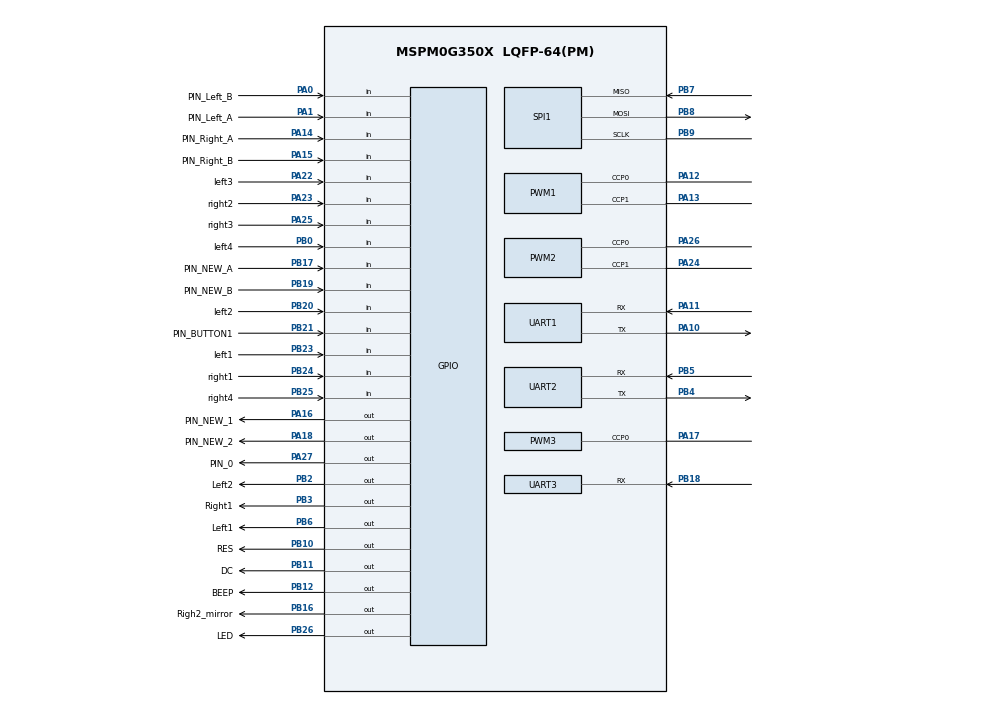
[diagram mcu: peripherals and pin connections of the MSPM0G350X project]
/**
 * @cliArgs --device "MSPM0G350X" --part "Default" --package "LQFP-64(PM)" --product "mspm0_sdk@2.10.00.04"
 * @versions {"tool":"1.26.2+4477"}
 */

/**
 * Import the modules used in this configuration.
 */
const GPIO    = scripting.addModule("/ti/driverlib/GPIO", {}, false);
const GPIO1   = GPIO.addInstance();
const GPIO2   = GPIO.addInstance();
const GPIO3   = GPIO.addInstance();
const GPIO4   = GPIO.addInstance();
const GPIO5   = GPIO.addInstance();
const GPIO6   = GPIO.addInstance();
const GPIO7   = GPIO.addInstance();
const GPIO8   = GPIO.addInstance();
const PWM     = scripting.addModule("/ti/driverlib/PWM", {}, false);
const PWM1    = PWM.addInstance();
const PWM2    = PWM.addInstance();
const PWM3    = PWM.addInstance();
const SPI     = scripting.addModule("/ti/driverlib/SPI", {}, false);
const SPI1    = SPI.addInstance();
const SYSCTL  = scripting.addModule("/ti/driverlib/SYSCTL");
const SYSTICK = scripting.addModule("/ti/driverlib/SYSTICK");
const TIMER   = scripting.addModule("/ti/driverlib/TIMER", {}, false);
const TIMER1  = TIMER.addInstance();
const UART    = scripting.addModule("/ti/driverlib/UART", {}, false);
const UART1   = UART.addInstance();
const UART2   = UART.addInstance();
const UART3   = UART.addInstance();

/**
 * Write custom configuration values to the imported modules.
 */
GPIO1.$name                         = "GPIO_MOTOR";
GPIO1.associatedPins.create(4);
GPIO1.associatedPins[0].$name       = "Left1";
GPIO1.associatedPins[0].pin.$assign = "PB6";
GPIO1.associatedPins[1].$name       = "Left2";
GPIO1.associatedPins[1].pin.$assign = "PB2";
GPIO1.associatedPins[2].$name       = "Right1";
GPIO1.associatedPins[2].pin.$assign = "PB3";
GPIO1.associatedPins[3].$name       = "Righ2_mirror";
GPIO1.associatedPins[3].pin.$assign = "PB16";

const Board = scripting.addModule("/ti/driverlib/Board", {}, false);

GPIO2.$name                          = "GPIO_LED";
GPIO2.associatedPins.create(2);
GPIO2.associatedPins[0].$name        = "LED";
GPIO2.associatedPins[0].initialValue = "SET";
GPIO2.associatedPins[0].pin.$assign  = "PB26";
GPIO2.associatedPins[1].$name        = "BEEP";
GPIO2.associatedPins[1].pin.$assign  = "PB12";

GPIO3.$name                         = "GPIO_Encoder";
GPIO3.associatedPins.create(6);
GPIO3.associatedPins[0].$name       = "PIN_Left_A";
GPIO3.associatedPins[0].direction   = "INPUT";
GPIO3.associatedPins[0].interruptEn = true;
GPIO3.associatedPins[0].polarity    = "RISE";
GPIO3.associatedPins[0].pin.$assign = "PA1";
GPIO3.associatedPins[1].$name       = "PIN_Left_B";
GPIO3.associatedPins[1].direction   = "INPUT";
GPIO3.associatedPins[1].pin.$assign = "PA0";
GPIO3.associatedPins[2].$name       = "PIN_Right_A";
GPIO3.associatedPins[2].direction   = "INPUT";
GPIO3.associatedPins[2].interruptEn = true;
GPIO3.associatedPins[2].polarity    = "RISE";
GPIO3.associatedPins[2].pin.$assign = "PA14";
GPIO3.associatedPins[3].$name       = "PIN_Right_B";
GPIO3.associatedPins[3].direction   = "INPUT";
GPIO3.associatedPins[3].pin.$assign = "PA15";
GPIO3.associatedPins[4].$name       = "PIN_NEW_A";
GPIO3.associatedPins[4].direction   = "INPUT";
GPIO3.associatedPins[4].polarity    = "RISE";
GPIO3.associatedPins[4].interruptEn = true;
GPIO3.associatedPins[4].pin.$assign = "PB17";
GPIO3.associatedPins[5].$name       = "PIN_NEW_B";
GPIO3.associatedPins[5].direction   = "INPUT";
GPIO3.associatedPins[5].pin.$assign = "PB19";

GPIO4.$name                              = "GPIO_BUTTON";
GPIO4.associatedPins.create(3);
GPIO4.associatedPins[0].$name            = "PIN_BUTTON1";
GPIO4.associatedPins[0].direction        = "INPUT";
GPIO4.associatedPins[0].internalResistor = "PULL_UP";
GPIO4.associatedPins[0].pin.$assign      = "PB21";
GPIO4.associatedPins[1].direction        = "INPUT";
GPIO4.associatedPins[1].internalResistor = "PULL_UP";
GPIO4.associatedPins[1].$name            = "PIN_BUTTON2";
GPIO4.associatedPins[2].$name            = "PIN_BUTTON3";
GPIO4.associatedPins[2].direction        = "INPUT";
GPIO4.associatedPins[2].internalResistor = "PULL_UP";

GPIO5.$name                         = "GPIO_Traking";
GPIO5.associatedPins.create(8);
GPIO5.associatedPins[0].direction   = "INPUT";
GPIO5.associatedPins[0].$name       = "left4";
GPIO5.associatedPins[0].pin.$assign = "PB0";
GPIO5.associatedPins[1].direction   = "INPUT";
GPIO5.associatedPins[1].$name       = "left3";
GPIO5.associatedPins[1].pin.$assign = "PA22";
GPIO5.associatedPins[2].direction   = "INPUT";
GPIO5.associatedPins[2].$name       = "left2";
GPIO5.associatedPins[2].pin.$assign = "PB20";
GPIO5.associatedPins[3].direction   = "INPUT";
GPIO5.associatedPins[3].$name       = "left1";
GPIO5.associatedPins[3].pin.$assign = "PB23";
GPIO5.associatedPins[4].direction   = "INPUT";
GPIO5.associatedPins[4].$name       = "right1";
GPIO5.associatedPins[4].pin.$assign = "PB24";
GPIO5.associatedPins[5].direction   = "INPUT";
GPIO5.associatedPins[5].$name       = "right2";
GPIO5.associatedPins[5].pin.$assign = "PA23";
GPIO5.associatedPins[6].direction   = "INPUT";
GPIO5.associatedPins[6].$name       = "right3";
GPIO5.associatedPins[6].pin.$assign = "PA25";
GPIO5.associatedPins[7].direction   = "INPUT";
GPIO5.associatedPins[7].$name       = "right4";
GPIO5.associatedPins[7].pin.$assign = "PB25";

GPIO6.$name                         = "OLED";
GPIO6.port                          = "PORTB";
GPIO6.associatedPins.create(3);
GPIO6.associatedPins[0].$name       = "RES";
GPIO6.associatedPins[0].ioStructure = "SD";
GPIO6.associatedPins[0].assignedPin = "10";
GPIO6.associatedPins[0].pin.$assign = "PB10";
GPIO6.associatedPins[1].$name       = "CS";
GPIO6.associatedPins[1].ioStructure = "SD";
GPIO6.associatedPins[1].assignedPin = "14";
GPIO6.associatedPins[2].$name       = "DC";
GPIO6.associatedPins[2].ioStructure = "SD";
GPIO6.associatedPins[2].assignedPin = "11";
GPIO6.associatedPins[2].pin.$assign = "PB11";

GPIO7.$name                         = "GPIO_MOTOR_NEW";
GPIO7.associatedPins.create(2);
GPIO7.associatedPins[0].$name       = "PIN_NEW_1";
GPIO7.associatedPins[0].pin.$assign = "PA16";
GPIO7.associatedPins[1].$name       = "PIN_NEW_2";
GPIO7.associatedPins[1].pin.$assign = "PA18";

GPIO8.$name                         = "GPIO_Voice";
GPIO8.associatedPins[0].$name       = "PIN_0";
GPIO8.associatedPins[0].pin.$assign = "PA27";

PWM1.$name                              = "PWM_MOTOR";
PWM1.timerCount                         = 3200;
PWM1.timerStartTimer                    = true;
PWM1.peripheral.ccp0Pin.$assign         = "PA12";
PWM1.peripheral.ccp1Pin.$assign         = "PA13";
PWM1.PWM_CHANNEL_0.$name                = "ti_driverlib_pwm_PWMTimerCC0";
PWM1.PWM_CHANNEL_1.$name                = "ti_driverlib_pwm_PWMTimerCC1";
PWM1.ccp0PinConfig.$name                = "ti_driverlib_gpio_GPIOPinGeneric0";
PWM1.ccp0PinConfig.direction            = scripting.forceWrite("OUTPUT");
PWM1.ccp0PinConfig.hideOutputInversion  = scripting.forceWrite(false);
PWM1.ccp0PinConfig.onlyInternalResistor = scripting.forceWrite(false);
PWM1.ccp0PinConfig.passedPeripheralType = scripting.forceWrite("Digital");
PWM1.ccp1PinConfig.$name                = "ti_driverlib_gpio_GPIOPinGeneric1";
PWM1.ccp1PinConfig.direction            = scripting.forceWrite("OUTPUT");
PWM1.ccp1PinConfig.hideOutputInversion  = scripting.forceWrite(false);
PWM1.ccp1PinConfig.onlyInternalResistor = scripting.forceWrite(false);
PWM1.ccp1PinConfig.passedPeripheralType = scripting.forceWrite("Digital");

PWM2.$name                              = "PWM_SEROR";
PWM2.clockPrescale                      = 32;
PWM2.timerCount                         = 20000;
PWM2.timerStartTimer                    = true;
PWM2.peripheral.$assign                 = "TIMG7";
PWM2.peripheral.ccp0Pin.$assign         = "PA26";
PWM2.peripheral.ccp1Pin.$assign         = "PA24";
PWM2.PWM_CHANNEL_0.$name                = "ti_driverlib_pwm_PWMTimerCC2";
PWM2.PWM_CHANNEL_1.$name                = "ti_driverlib_pwm_PWMTimerCC3";
PWM2.ccp0PinConfig.direction            = scripting.forceWrite("OUTPUT");
PWM2.ccp0PinConfig.hideOutputInversion  = scripting.forceWrite(false);
PWM2.ccp0PinConfig.onlyInternalResistor = scripting.forceWrite(false);
PWM2.ccp0PinConfig.passedPeripheralType = scripting.forceWrite("Digital");
PWM2.ccp0PinConfig.$name                = "ti_driverlib_gpio_GPIOPinGeneric9";
PWM2.ccp1PinConfig.direction            = scripting.forceWrite("OUTPUT");
PWM2.ccp1PinConfig.hideOutputInversion  = scripting.forceWrite(false);
PWM2.ccp1PinConfig.onlyInternalResistor = scripting.forceWrite(false);
PWM2.ccp1PinConfig.passedPeripheralType = scripting.forceWrite("Digital");
PWM2.ccp1PinConfig.$name                = "ti_driverlib_gpio_GPIOPinGeneric10";

PWM3.timerCount                         = 3200;
PWM3.timerStartTimer                    = true;
PWM3.ccIndex                            = [0];
PWM3.$name                              = "PWM_SEROR_NEW";
PWM3.PWM_CHANNEL_0.$name                = "ti_driverlib_pwm_PWMTimerCC4";
PWM3.ccp0PinConfig.direction            = scripting.forceWrite("OUTPUT");
PWM3.ccp0PinConfig.hideOutputInversion  = scripting.forceWrite(false);
PWM3.ccp0PinConfig.onlyInternalResistor = scripting.forceWrite(false);
PWM3.ccp0PinConfig.passedPeripheralType = scripting.forceWrite("Digital");
PWM3.ccp0PinConfig.$name                = "ti_driverlib_gpio_GPIOPinGeneric11";
PWM3.peripheral.$assign                 = "TIMA1";
PWM3.peripheral.ccp0Pin.$assign         = "PA17";

SPI1.$name                              = "SPI_OLED";
SPI1.frameFormat                        = "MOTO3";
SPI1.sclkPinConfig.$name                = "ti_driverlib_gpio_GPIOPinGeneric6";
SPI1.sclkPinConfig.direction            = scripting.forceWrite("OUTPUT");
SPI1.sclkPinConfig.onlyInternalResistor = scripting.forceWrite(false);
SPI1.sclkPinConfig.passedPeripheralType = scripting.forceWrite("Digital");
SPI1.mosiPinConfig.$name                = "ti_driverlib_gpio_GPIOPinGeneric7";
SPI1.mosiPinConfig.direction            = scripting.forceWrite("OUTPUT");
SPI1.mosiPinConfig.hideOutputInversion  = scripting.forceWrite(false);
SPI1.mosiPinConfig.onlyInternalResistor = scripting.forceWrite(false);
SPI1.mosiPinConfig.passedPeripheralType = scripting.forceWrite("Digital");
SPI1.misoPinConfig.$name                = "ti_driverlib_gpio_GPIOPinGeneric8";
SPI1.misoPinConfig.onlyInternalResistor = scripting.forceWrite(false);
SPI1.misoPinConfig.passedPeripheralType = scripting.forceWrite("Digital");
SPI1.peripheral.$assign                 = "SPI1";
SPI1.peripheral.sclkPin.$assign         = "PB9";
SPI1.peripheral.mosiPin.$assign         = "PB8";
SPI1.peripheral.misoPin.$assign         = "PB7";

SYSCTL.forceDefaultClkConfig = true;

SYSTICK.periodEnable      = true;
SYSTICK.period            = 32000;
SYSTICK.interruptEnable   = true;
SYSTICK.systickEnable     = true;
SYSTICK.interruptPriority = "0";

TIMER1.$name             = "TIMER_0";
TIMER1.timerClkDiv       = 4;
TIMER1.timerStartTimer   = true;
TIMER1.timerMode         = "PERIODIC";
TIMER1.interrupts        = ["ZERO"];
TIMER1.interruptPriority = "2";
TIMER1.timerPeriod       = "10ms";
TIMER1.timerClkPrescale  = 25;

UART1.$name                    = "UART_0";
UART1.enabledInterrupts        = ["RX"];
UART1.peripheral.rxPin.$assign = "PA11";
UART1.peripheral.txPin.$assign = "PA10";
UART1.txPinConfig.$name        = "ti_driverlib_gpio_GPIOPinGeneric2";
UART1.rxPinConfig.$name        = "ti_driverlib_gpio_GPIOPinGeneric3";

UART2.$name                            = "UART_OpenMv";
UART2.targetBaudRate                   = 115200;
UART2.enabledInterrupts                = ["RX"];
UART2.peripheral.rxPin.$assign         = "PB5";
UART2.peripheral.txPin.$assign         = "PB4";
UART2.txPinConfig.direction            = scripting.forceWrite("OUTPUT");
UART2.txPinConfig.hideOutputInversion  = scripting.forceWrite(false);
UART2.txPinConfig.onlyInternalResistor = scripting.forceWrite(false);
UART2.txPinConfig.passedPeripheralType = scripting.forceWrite("Digital");
UART2.txPinConfig.$name                = "ti_driverlib_gpio_GPIOPinGeneric4";
UART2.rxPinConfig.hideOutputInversion  = scripting.forceWrite(false);
UART2.rxPinConfig.onlyInternalResistor = scripting.forceWrite(false);
UART2.rxPinConfig.passedPeripheralType = scripting.forceWrite("Digital");
UART2.rxPinConfig.$name                = "ti_driverlib_gpio_GPIOPinGeneric5";

UART3.$name                            = "UART_WIT";
UART3.targetBaudRate                   = 115200;
UART3.direction                        = "RX";
UART3.enableFIFO                       = true;
UART3.rxTimeoutValue                   = 1;
UART3.enabledInterrupts                = ["RX_TIMEOUT_ERROR"];
UART3.enabledDMARXTriggers             = "DL_UART_DMA_INTERRUPT_RX";
UART3.rxPinConfig.hideOutputInversion  = scripting.forceWrite(false);
UART3.rxPinConfig.onlyInternalResistor = scripting.forceWrite(false);
UART3.rxPinConfig.passedPeripheralType = scripting.forceWrite("Digital");
UART3.rxPinConfig.$name                = "ti_driverlib_gpio_GPIOPinGeneric12";
UART3.peripheral.$assign               = "UART2";
UART3.peripheral.rxPin.$assign         = "PB18";
UART3.DMA_CHANNEL_RX.$name             = "DMA_WIT";
UART3.DMA_CHANNEL_RX.addressMode       = "f2b";
UART3.DMA_CHANNEL_RX.srcLength         = "BYTE";
UART3.DMA_CHANNEL_RX.dstLength         = "BYTE";

/**
 * Pinmux solution for unlocked pins/peripherals. This ensures that minor changes to the automatic solver in a future
 * version of the tool will not impact the pinmux you originally saw.  These lines can be completely deleted in order to
 * re-solve from scratch.
 */
Board.peripheral.$suggestSolution                = "DEBUGSS";
Board.peripheral.swclkPin.$suggestSolution       = "PA20";
Board.peripheral.swdioPin.$suggestSolution       = "PA19";
GPIO4.associatedPins[1].pin.$suggestSolution     = "PB15";
GPIO4.associatedPins[2].pin.$suggestSolution     = "PB13";
GPIO6.associatedPins[1].pin.$suggestSolution     = "PB14";
PWM1.peripheral.$suggestSolution                 = "TIMG0";
SYSCTL.peripheral.$suggestSolution               = "SYSCTL";
TIMER1.peripheral.$suggestSolution               = "TIMA0";
UART1.peripheral.$suggestSolution                = "UART0";
UART2.peripheral.$suggestSolution                = "UART1";
UART3.DMA_CHANNEL_RX.peripheral.$suggestSolution = "DMA_CH0";
